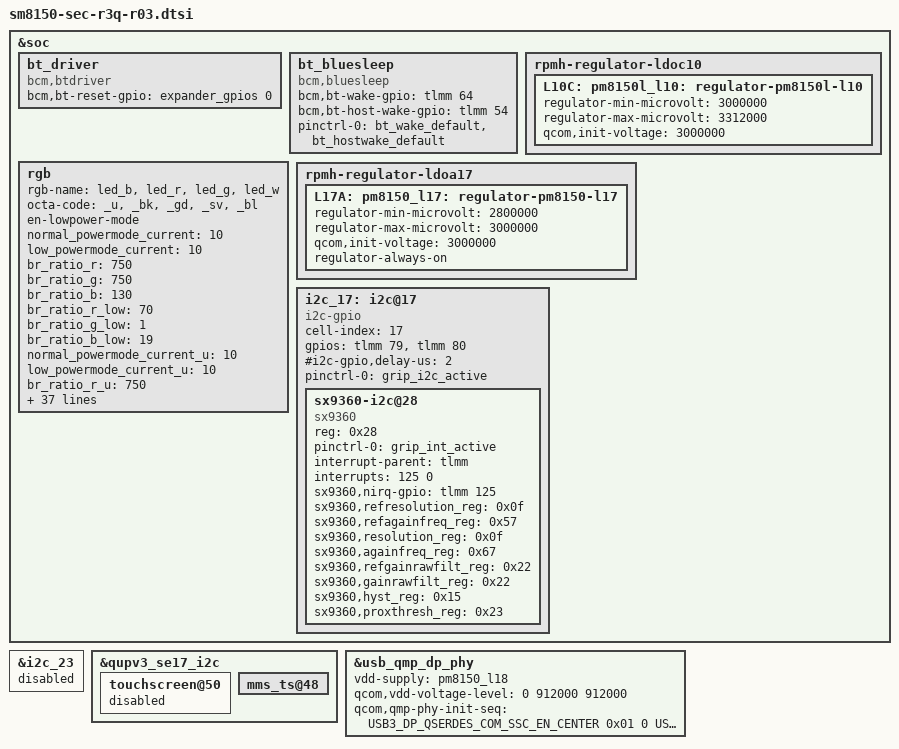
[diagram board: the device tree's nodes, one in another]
/* Copyright (c) 2016-2017, The Linux Foundation. All rights reserved.
 *
 * This program is free software; you can redistribute it and/or modify
 * it under the terms of the GNU General Public License version 2 and
 * only version 2 as published by the Free Software Foundation.
 *
 * This program is distributed in the hope that it will be useful,
 * but WITHOUT ANY WARRANTY; without even the implied warranty of
 * MERCHANTABILITY or FITNESS FOR A PARTICULAR PURPOSE.  See the
 * GNU General Public License for more details.
 */

#include "sm8150-sec-r3q-common.dtsi"

&soc {
	bt_driver {
		compatible = "bcm,btdriver";  //bt_en
		pinctrl-names = "default";
		bcm,bt-reset-gpio = <&expander_gpios 0 GPIO_ACTIVE_HIGH>;
		status = "okay";
	};

	bt_bluesleep {
		compatible = "bcm,bluesleep";
		bcm,bt-wake-gpio = <&tlmm 64 0>;
		bcm,bt-host-wake-gpio = <&tlmm 54 0>;
		pinctrl-names = "default";
		pinctrl-0 = <&bt_wake_default &bt_hostwake_default>;
		status = "okay";
	};
	
	/* for WIFI */
	rpmh-regulator-ldoc10 {
		L10C: pm8150l_l10: regulator-pm8150l-l10 {
			regulator-min-microvolt = <3000000>;
			regulator-max-microvolt = <3312000>;
			qcom,init-voltage = <3000000>;
		};
	};

	rgb {
		device_type = "star1";
		rgb-name = "led_b", "led_r", "led_g", "led_w";
		octa-code = "_u", "_bk", "_gd", "_sv", "_bl";

		en-lowpower-mode;

		normal_powermode_current = <10>;
		low_powermode_current = <10>;
		br_ratio_r = <750>;
		br_ratio_g = <750>;
		br_ratio_b = <130>;
		br_ratio_r_low = <70>;
		br_ratio_g_low = <1>;
		br_ratio_b_low = <19>;

		normal_powermode_current_u = <10>;
		low_powermode_current_u = <10>;
		br_ratio_r_u = <750>;
		br_ratio_g_u = <370>;
		br_ratio_b_u = <130>;
		br_ratio_r_low_u = <70>;
		br_ratio_g_low_u = <1>;
		br_ratio_b_low_u = <19>;

		normal_powermode_current_bk = <10>;
		low_powermode_current_bk = <10>;
		br_ratio_r_bk = <750>;
		br_ratio_g_bk = <70>;
		br_ratio_b_bk = <130>;
		br_ratio_r_low_bk = <70>;
		br_ratio_g_low_bk = <1>;
		br_ratio_b_low_bk = <19>;

		normal_powermode_current_gd = <10>;
		low_powermode_current_gd = <10>;
		br_ratio_r_gd = <750>;
		br_ratio_g_gd = <70>;
		br_ratio_b_gd = <130>;
		br_ratio_r_low_gd = <70>;
		br_ratio_g_low_gd = <1>;
		br_ratio_b_low_gd = <19>;

		normal_powermode_current_sv = <10>;
		low_powermode_current_sv = <10>;
		br_ratio_r_sv = <750>;
		br_ratio_g_sv = <70>;
		br_ratio_b_sv = <130>;
		br_ratio_r_low_sv = <70>;
		br_ratio_g_low_sv = <1>;
		br_ratio_b_low_sv = <19>;

		normal_powermode_current_bl = <10>;
		low_powermode_current_bl = <10>;
		br_ratio_r_bl = <750>;
		br_ratio_g_bl = <70>;
		br_ratio_b_bl = <130>;
		br_ratio_r_low_bl = <70>;
		br_ratio_g_low_bl = <1>;
		br_ratio_b_low_bl = <19>;
	};

	rpmh-regulator-ldoa17 {
		L17A: pm8150_l17: regulator-pm8150-l17 {
			regulator-min-microvolt = <2800000>;
			regulator-max-microvolt = <3000000>;
			qcom,init-voltage = <3000000>;
			regulator-always-on;
		};
	};

	i2c_17: i2c@17 { /* SW I2C */
		status = "ok";

		cell-index = <17>;
		compatible = "i2c-gpio";
		gpios = <&tlmm 79 0 /* sda */
			 &tlmm 80 0 /* scl */
		>;
		#i2c-gpio,delay-us = <2>;
		#address-cells = <1>;
		#size-cells = <0>;
		pinctrl-names = "default";
		pinctrl-0 = <&grip_i2c_active>;

		sx9360-i2c@28 {
			compatible = "sx9360";
			reg = <0x28>;
			status = "okay";
			pinctrl-names = "default";
			pinctrl-0 = <&grip_int_active>;
			interrupt-parent = <&tlmm>;
			interrupts = <125 0>;

			sx9360,nirq-gpio = <&tlmm 125 0>;
			sx9360,refresolution_reg = <0x0f>; /* same as resolution_reg */
			sx9360,refagainfreq_reg = <0x57>; /* same as againfreq_reg */
			sx9360,resolution_reg = <0x0f>; /* resolution : 1024 */
			sx9360,againfreq_reg = <0x67>; /* freq : 71.43 kHz, again : +/-9 pF */
			sx9360,refgainrawfilt_reg = <0x22>; /* same as gainrawfilt_reg */
			sx9360,gainrawfilt_reg = <0x22>; /* rawfilter : 1-1/4, gain : x8 */
			sx9360,hyst_reg = <0x15>; /* hysteresis : +/-6 %, debouncer : 2 samples */
			sx9360,proxthresh_reg = <0x23>; /* threshhold : 612 */
		};
	};
};

&i2c_23 {
	status = "disabled";
};

&qupv3_se17_i2c {
	touchscreen@50 {
		status = "disabled";
	};
	mms_ts@48 {
		status = "ok";
	};
};

&usb_qmp_dp_phy {
	vdd-supply = <&pm8150_l18>;
	qcom,vdd-voltage-level = <0 912000 912000>;
	qcom,qmp-phy-init-seq =
	    <USB3_DP_QSERDES_COM_SSC_EN_CENTER 0x01 0
	     USB3_DP_QSERDES_COM_SSC_PER1 0x31 0
	     USB3_DP_QSERDES_COM_SSC_PER2 0x01 0
	     USB3_DP_QSERDES_COM_SSC_STEP_SIZE1_MODE0 0xde 0
	     USB3_DP_QSERDES_COM_SSC_STEP_SIZE2_MODE0 0x07 0
	     USB3_DP_QSERDES_COM_SSC_STEP_SIZE1_MODE1 0xde 0
	     USB3_DP_QSERDES_COM_SSC_STEP_SIZE2_MODE1 0x07 0
	     USB3_DP_QSERDES_COM_SYSCLK_BUF_ENABLE 0x0a 0
	     USB3_DP_QSERDES_COM_CP_CTRL_MODE0 0x06 0
	     USB3_DP_QSERDES_COM_CP_CTRL_MODE1 0x06 0
	     USB3_DP_QSERDES_COM_PLL_RCTRL_MODE0 0x16 0
	     USB3_DP_QSERDES_COM_PLL_RCTRL_MODE1 0x16 0
	     USB3_DP_QSERDES_COM_PLL_CCTRL_MODE0 0x36 0
	     USB3_DP_QSERDES_COM_PLL_CCTRL_MODE1 0x36 0
	     USB3_DP_QSERDES_COM_SYSCLK_EN_SEL 0x1a 0
	     USB3_DP_QSERDES_COM_LOCK_CMP_EN 0x04 0
	     USB3_DP_QSERDES_COM_LOCK_CMP1_MODE0 0x14 0
	     USB3_DP_QSERDES_COM_LOCK_CMP2_MODE0 0x34 0
	     USB3_DP_QSERDES_COM_LOCK_CMP1_MODE1 0x34 0
	     USB3_DP_QSERDES_COM_LOCK_CMP2_MODE1 0x82 0
	     USB3_DP_QSERDES_COM_DEC_START_MODE0 0x82 0
	     USB3_DP_QSERDES_COM_DEC_START_MODE1 0x82 0
	     USB3_DP_QSERDES_COM_DIV_FRAC_START1_MODE0 0xab 0
	     USB3_DP_QSERDES_COM_DIV_FRAC_START2_MODE0 0xea 0
	     USB3_DP_QSERDES_COM_DIV_FRAC_START3_MODE0 0x02 0
	     USB3_DP_QSERDES_COM_DIV_FRAC_START1_MODE1 0xab 0
	     USB3_DP_QSERDES_COM_DIV_FRAC_START2_MODE1 0xea 0
	     USB3_DP_QSERDES_COM_DIV_FRAC_START3_MODE1 0x02 0
	     USB3_DP_QSERDES_COM_VCO_TUNE1_MODE0 0x24 0
	     USB3_DP_QSERDES_COM_VCO_TUNE1_MODE1 0x24 0
	     USB3_DP_QSERDES_COM_VCO_TUNE2_MODE1 0x02 0
	     USB3_DP_QSERDES_COM_HSCLK_SEL 0x01 0
	     USB3_DP_QSERDES_COM_CORECLK_DIV_MODE1 0x08 0
	     USB3_DP_QSERDES_COM_SVS_MODE_CLK_SEL 0x2 0
	     USB3_DP_QSERDES_COM_BIN_VCOCAL_CMP_CODE1_MODE0 0xca 0
	     USB3_DP_QSERDES_COM_BIN_VCOCAL_CMP_CODE2_MODE0 0x1e 0
	     USB3_DP_QSERDES_COM_BIN_VCOCAL_CMP_CODE1_MODE1 0xca 0
	     USB3_DP_QSERDES_COM_BIN_VCOCAL_CMP_CODE2_MODE1 0x1e 0
	     USB3_DP_QSERDES_COM_BIN_VCOCAL_HSCLK_SEL 0x11 0
	     USB3_DP_QSERDES_COM_VCO_TUNE_MAP 0x02 0
	     USB3_DP_QSERDES_COM_CMN_IPTRIM 0x20 0
	     USB3_DP_QSERDES_TXA_LANE_MODE_1 0xd5 0
	     USB3_DP_QSERDES_TXA_RCV_DETECT_LVL_2 0x12 0
	     USB3_DP_QSERDES_TXA_RES_CODE_LANE_TX 0x00 0
	     USB3_DP_QSERDES_TXA_RES_CODE_LANE_RX 0x00 0
	     USB3_DP_QSERDES_TXA_RES_CODE_LANE_OFFSET_TX 0x16 0
	     USB3_DP_QSERDES_TXA_RES_CODE_LANE_OFFSET_RX 0x05 0
	     USB3_DP_QSERDES_TXA_PI_QEC_CTRL 0x20 0
	     USB3_DP_QSERDES_RXA_UCDR_SO_GAIN 0x04 0
	     USB3_DP_QSERDES_RXA_UCDR_FASTLOCK_FO_GAIN 0x2f 0
	     USB3_DP_QSERDES_RXA_UCDR_SO_SATURATION_AND_ENABLE 0x7f 0
	     USB3_DP_QSERDES_RXA_UCDR_FASTLOCK_COUNT_LOW 0xff 0
	     USB3_DP_QSERDES_RXA_UCDR_FASTLOCK_COUNT_HIGH 0x0f 0
	     USB3_DP_QSERDES_RXA_UCDR_PI_CONTROLS 0x99 0
	     USB3_DP_QSERDES_RXA_UCDR_SB2_THRESH1 0x04 0
	     USB3_DP_QSERDES_RXA_UCDR_SB2_THRESH2 0x08 0
	     USB3_DP_QSERDES_RXA_UCDR_SB2_GAIN1 0x05 0
	     USB3_DP_QSERDES_RXA_UCDR_SB2_GAIN2 0x05 0
	     USB3_DP_QSERDES_RXA_AUX_DATA_TCOARSE_TFINE 0xa0 0
	     USB3_DP_QSERDES_RXA_VGA_CAL_CNTRL1 0x54 0
	     USB3_DP_QSERDES_RXA_VGA_CAL_CNTRL2 0x0e 0
	     USB3_DP_QSERDES_RXA_GM_CAL 0x1f 0
	     USB3_DP_QSERDES_RXA_RX_EQU_ADAPTOR_CNTRL2 0x0f 0
	     USB3_DP_QSERDES_RXA_RX_EQU_ADAPTOR_CNTRL3 0x4a 0
	     USB3_DP_QSERDES_RXA_RX_EQU_ADAPTOR_CNTRL4 0x0a 0
	     USB3_DP_QSERDES_RXA_RX_IDAC_TSETTLE_LOW 0xc0 0
	     USB3_DP_QSERDES_RXA_RX_IDAC_TSETTLE_HIGH 0x00 0
	     USB3_DP_QSERDES_RXA_RX_EQ_OFFSET_ADAPTOR_CNTRL1 0x77 0
	     USB3_DP_QSERDES_RXA_RX_OFFSET_ADAPTOR_CNTRL2 0x80 0
	     USB3_DP_QSERDES_RXA_SIGDET_CNTRL 0x04 0
	     USB3_DP_QSERDES_RXA_SIGDET_DEGLITCH_CNTRL 0x0e 0
	     USB3_DP_QSERDES_RXA_RX_MODE_00_LOW 0xbf 0
	     USB3_DP_QSERDES_RXA_RX_MODE_00_HIGH 0xbf 0
	     USB3_DP_QSERDES_RXA_RX_MODE_00_HIGH2 0x3f 0
	     USB3_DP_QSERDES_RXA_RX_MODE_00_HIGH3 0x7f 0
	     USB3_DP_QSERDES_RXA_RX_MODE_00_HIGH4 0x94 0
	     USB3_DP_QSERDES_RXA_RX_MODE_01_LOW 0xdc 0
	     USB3_DP_QSERDES_RXA_RX_MODE_01_HIGH 0xdc 0
	     USB3_DP_QSERDES_RXA_RX_MODE_01_HIGH2 0x5c 0
	     USB3_DP_QSERDES_RXA_RX_MODE_01_HIGH3 0x0b 0
	     USB3_DP_QSERDES_RXA_RX_MODE_01_HIGH4 0xb6 0
	     USB3_DP_QSERDES_RXA_DFE_EN_TIMER 0x04 0
	     USB3_DP_QSERDES_RXA_DFE_CTLE_POST_CAL_OFFSET 0x38 0
	     USB3_DP_QSERDES_RXA_DCC_CTRL1 0xc 0
	     USB3_DP_QSERDES_RXA_VTH_CODE 0x10 0
	     USB3_DP_QSERDES_TXB_LANE_MODE_1 0xd5 0
	     USB3_DP_QSERDES_TXB_RCV_DETECT_LVL_2 0x12 0
	     USB3_DP_QSERDES_TXB_RES_CODE_LANE_TX 0x00 0
	     USB3_DP_QSERDES_TXB_RES_CODE_LANE_RX 0x00 0
	     USB3_DP_QSERDES_TXB_RES_CODE_LANE_OFFSET_TX 0x16 0
	     USB3_DP_QSERDES_TXB_RES_CODE_LANE_OFFSET_RX 0x05 0
	     USB3_DP_QSERDES_TXB_PI_QEC_CTRL 0x20 0
	     USB3_DP_QSERDES_RXB_UCDR_SO_GAIN 0x04 0
	     USB3_DP_QSERDES_RXB_UCDR_FASTLOCK_FO_GAIN 0x2f 0
	     USB3_DP_QSERDES_RXB_UCDR_SO_SATURATION_AND_ENABLE 0x7f 0
	     USB3_DP_QSERDES_RXB_UCDR_FASTLOCK_COUNT_LOW 0xff 0
	     USB3_DP_QSERDES_RXB_UCDR_FASTLOCK_COUNT_HIGH 0x0f 0
	     USB3_DP_QSERDES_RXB_UCDR_PI_CONTROLS 0x99 0
	     USB3_DP_QSERDES_RXB_UCDR_SB2_THRESH1 0x04 0
	     USB3_DP_QSERDES_RXB_UCDR_SB2_THRESH2 0x08 0
	     USB3_DP_QSERDES_RXB_UCDR_SB2_GAIN1 0x05 0
	     USB3_DP_QSERDES_RXB_UCDR_SB2_GAIN2 0x05 0
	     USB3_DP_QSERDES_RXB_AUX_DATA_TCOARSE_TFINE 0xa0 0
	     USB3_DP_QSERDES_RXB_VGA_CAL_CNTRL1 0x54 0
	     USB3_DP_QSERDES_RXB_VGA_CAL_CNTRL2 0x0e 0
	     USB3_DP_QSERDES_RXB_GM_CAL 0x1f 0
	     USB3_DP_QSERDES_RXB_RX_EQU_ADAPTOR_CNTRL2 0x0f 0
	     USB3_DP_QSERDES_RXB_RX_EQU_ADAPTOR_CNTRL3 0x4a 0
	     USB3_DP_QSERDES_RXB_RX_EQU_ADAPTOR_CNTRL4 0x0a 0
	     USB3_DP_QSERDES_RXB_RX_IDAC_TSETTLE_LOW 0xc0 0
	     USB3_DP_QSERDES_RXB_RX_IDAC_TSETTLE_HIGH 0x00 0
	     USB3_DP_QSERDES_RXB_RX_EQ_OFFSET_ADAPTOR_CNTRL1 0x77 0
	     USB3_DP_QSERDES_RXB_RX_OFFSET_ADAPTOR_CNTRL2 0x80 0
	     USB3_DP_QSERDES_RXB_SIGDET_CNTRL 0x04 0
	     USB3_DP_QSERDES_RXB_SIGDET_DEGLITCH_CNTRL 0x0e 0
	     USB3_DP_QSERDES_RXB_RX_MODE_00_LOW 0xbf 0
	     USB3_DP_QSERDES_RXB_RX_MODE_00_HIGH 0xbf 0
	     USB3_DP_QSERDES_RXB_RX_MODE_00_HIGH2 0x3f 0
	     USB3_DP_QSERDES_RXB_RX_MODE_00_HIGH3 0x7f 0
	     USB3_DP_QSERDES_RXB_RX_MODE_00_HIGH4 0x94 0
	     USB3_DP_QSERDES_RXB_RX_MODE_01_LOW 0xdc 0
	     USB3_DP_QSERDES_RXB_RX_MODE_01_HIGH 0xdc 0
	     USB3_DP_QSERDES_RXB_RX_MODE_01_HIGH2 0x5c 0
	     USB3_DP_QSERDES_RXB_RX_MODE_01_HIGH3 0x0b 0
	     USB3_DP_QSERDES_RXB_RX_MODE_01_HIGH4 0xb6 0
	     USB3_DP_QSERDES_RXB_DFE_EN_TIMER 0x04 0
	     USB3_DP_QSERDES_RXB_DFE_CTLE_POST_CAL_OFFSET 0x38 0
	     USB3_DP_QSERDES_RXB_DCC_CTRL1 0xc 0
	     USB3_DP_QSERDES_RXB_VTH_CODE 0x10 0
	     USB3_DP_PCS_LOCK_DETECT_CONFIG1 0xd0 0
	     USB3_DP_PCS_LOCK_DETECT_CONFIG2 0x17 0
	     USB3_DP_PCS_LOCK_DETECT_CONFIG3 0x20 0
	     USB3_DP_PCS_RX_SIGDET_LVL 0xaa 0
	     USB3_DP_PCS_ALIGN_DETECT_CONFIG1 0x88 0
	     USB3_DP_PCS_ALIGN_DETECT_CONFIG2 0x13 0
	     USB3_DP_PCS_EQ_CONFIG1 0x0d 0
	     USB3_DP_PCS_EQ_CONFIG5 0x50 0
	     USB3_DP_PCS_USB3_LFPS_DET_HIGH_COUNT_VAL 0xf8 0
	     USB3_DP_PCS_USB3_RXEQTRAINING_DFE_TIME_S2 0x07 0
	     0xffffffff 0xffffffff 0x00>;
};
